# PIC32CX2051MTSH128S1 register map
Vendor: Microchip Technology; Series: PIC32CXMTSH; File version: 0
CPU: CM4 r0p1, selectable endian, MPU, FPU, 4 interrupt priority bits
Registers are 32-bit, read-write, reset 0x0 unless marked. A register's access mark holds for its fields unless they carry their own. Offsets are from the block's base; [hi:lo] are bit positions; {n}, {i} and the like mark numbered series; 'fields as' and 'values as' point back to an identical list.

## SUPC — Supply Controller
Base 0x400531D0; register names take the prefix SUPC_
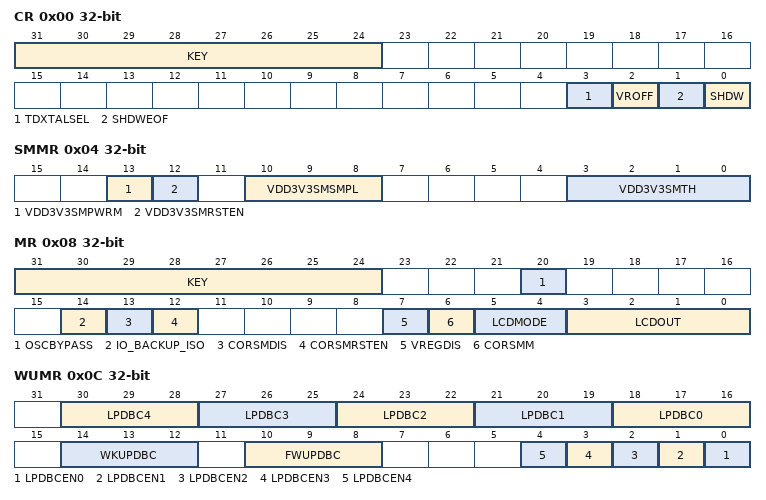
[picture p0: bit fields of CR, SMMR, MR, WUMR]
0x00 CR wo — Control Register
  [31:24] KEY — Password
    165=PASSWD (Writing any other value in this field aborts the write operation.)
  [3] TDXTALSEL — Timing Domain Slow Clock Selector
    0=RC (Slow clock of the timing domain is driven by the embedded 32 kHz (typical) RC oscillator.); 1=XTAL (Slow clock of the timing domain is driven by the 32.768 kHz crystal oscillator.)
  [2] VROFF — Voltage Regulator Off
    0=NO_EFFECT; 1=STOP_VREG (If KEY=0xA5, VROFF asserts the VDDCORE domain reset and stops the voltage regulator.)
  [1] SHDWEOF — Shutdown End Of Frame
  [0] SHDW — Shutdown
0x04 SMMR — Supply Monitor Mode Register
  [13] VDD3V3SMPWRM — VDD3V3 Supply Monitor Power Supply Mode
    0=MANUAL (The VDDBU power source selection is controlled by configuring the bit RSTC_MR.PWRSW.); 1=AUTO_VDD3V3SM (The VDDBU power source is VBAT when a VDD3V3 undervoltage is detected by the VDD3V3 supply monitor.)
  [12] VDD3V3SMRSTEN — VDD3V3 Supply Monitor Reset Enable
  [10:8] VDD3V3SMSMPL — VDD3V3 Supply Monitor Sampling Period
    0=DISABLED (VDD3V3 supply monitor is disabled); 1=ALWAYS_ON (Continuous VDD3V3 supply monitoring); 2=_32SLCK (VDD3V3 supply monitor is enabled for 1 period every 32 MD_SLCK periods Energy optimization in Backup mode with VDD3V3 supplied.); 3=_256SLCK (VDD3V3 supply monitor is enabled for 1 period every 256 MD_SLCK periods Energy optimization in Backup mode with VDD3V3 supplied.); 4=_2048SLCK (VDD3V3 supply monitor is enabled for 1 period every 2048 MD_SLCK periods Energy optimization in Backup mode with VDD3V3 supplied.)
  [3:0] VDD3V3SMTH — VDD3V3 Supply Monitor Threshold
0x08 MR — Mode Register
  [31:24] KEY — Password Key
    89=PASSWD1 (Modifies the VREGDIS bit. Other bits are not affected.); 165=PASSWD (Writing any other value in this field aborts the write operation.)
  [20] OSCBYPASS — Slow Crystal Oscillator Bypass
    0=NO_EFFECT (No effect. Clock selection depends on the value of the bit SUPC_CR.TDXTALSEL.); 1=BYPASS (The slow crystal oscillator is bypassed if SUPC_CR.TDXTALSEL=1. The bit OSCBYPASS must be set prior to setting the bit TDXTALSEL.)
  [14] IO_BACKUP_ISO — Backup Domain IO Isolation Control
  [13] CORSMDIS — VDDCORE Supply Monitor Disable
  [12] CORSMRSTEN — VDDCORE Supply Monitor Reset Enable
  [7] VREGDIS — Internal VDDCORE Voltage Regulator Disable
    0=INT_VREG (Internal VDDCORE voltage regulator is enabled.); 1=EXT_VREG (Internal VDDCORE voltage regulator is disabled (external power supply is used).)
  [6] CORSMM — VDDCORE Supply Monitor Output Mode
    0=NO_EFFECT (VDDCORE supply monitor output value has no effect. Power-on is performed whatever the value of the supply monitor output.); 1=VALID_VDD (VDDCORE supply monitor output value is checked to validate the VDDCORE domain power-on.)
  [5:4] LCDMODE — LCD Controller Mode of Operation
    0=LCDOFF (The internal supply source and the external supply source are both deselected (OFF Mode).); 2=LCDON_EXTVR (The external supply source for LCD (VDDLCD) is selected (the embedded LCD voltage regulator is in High-impedance mode).); 3=LCDON_INVR (The internal voltage regulator for VDDLCD is selected (Active mode).)
  [3:0] LCDOUT — LCD Voltage Regulator Output
0x0C WUMR — Wakeup Mode Register
  [3n+18:3n+16] LPDBC{n} (n=0..4) — Low-power Debouncer Period of WKUPx
    0=DISABLE (Disables the low-power debouncers.); {v}=_{v+1}_RTCOUT (WKUPx in active state for at least {v+1} RTCOUTx clock periods) (v=1..7)
  [14:12] WKUPDBC — Wake-up Inputs Debouncer Period
    0=IMMEDIATE (Immediate, no debouncing, detected active at least on one Slow Clock edge.); 1=_3_SK (WKUPx shall be in its active state for at least 3 MD_SLCK periods); 2=_32_SK (WKUPx shall be in its active state for at least 32 MD_SLCK periods); 3=_512_SK (WKUPx shall be in its active state for at least 512 MD_SLCK periods); 4=_4096_SK (WKUPx shall be in its active state for at least 4,096 MD_SLCK periods); 5=_32768_SK (WKUPx shall be in its active state for at least 32,768 MD_SLCK periods)
  [10:8] FWUPDBC — Force Wake-up Inputs Debouncer Period
    values as WKUPDBC
  [n] LPDBCEN{n} (n=0..4) — Tamper Enable for WKUPx Pin
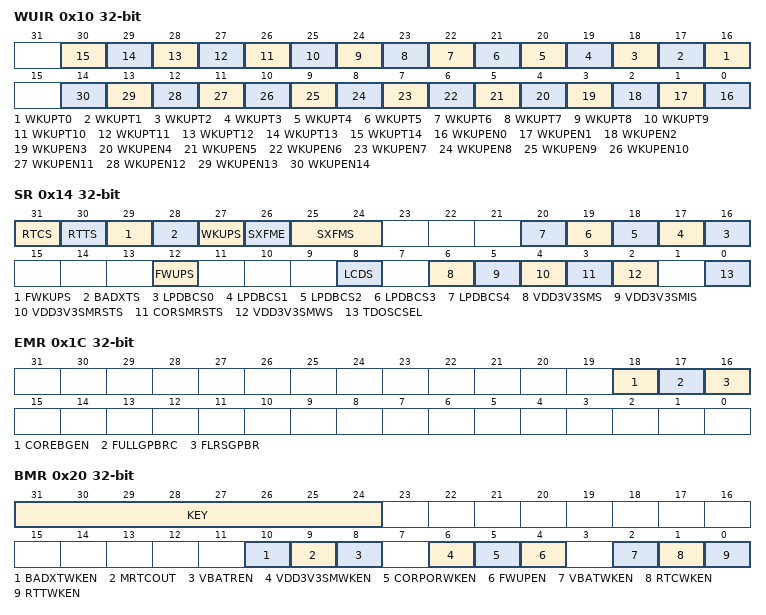
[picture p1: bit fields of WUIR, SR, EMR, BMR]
0x10 WUIR — Wakeup Inputs Register
  [n+16] WKUPT{n} (n=0..14) — Wake-up Input Type {n}
    0=LOW (A falling edge followed by a low level for a period defined by WKUPDBC on the corresponding wake-up input forces the wake-up of the core power supply.); 1=HIGH (A rising edge followed by a high level for a period defined by WKUPDBC on the corresponding wake-up input forces the wake-up of the core power supply.)
  [n] WKUPEN{n} (n=0..14) — Wake-up Input Enable {n}
0x14 SR ro — Status Register
  [31] RTCS — RTC Wake-up Status (cleared by reading SUPC_WUSR)
  [30] RTTS — RTT Wake-up Status (cleared by reading SUPC_WUSR)
  [29] FWKUPS — FWUP Wake-up Status (cleared by reading SUPC_WUSR)
  [28] BADXTS — Slow Crystal Oscillator Wake-up Status (cleared by reading SUPC_WUSR)
  [27] WKUPS — WKUP Wake-up Status (cleared by reading SUPC_WUSR)
  [26] SXFME — Slow Crystal Oscillator Frequency Monitor Error (cleared on read)
  [25:24] SXFMS — Slow Crystal Oscillator Frequency Monitor Status (cleared on read)
    0=GOOD (No frequency error detected.); 1=FREQ_ERROR (The frequency has not been correct over 4 consecutive monitoring periods but there are still edges detected on the slow crystal oscillator output.); 2=FAIL (No edge detected in the slow crystal oscillator output for at least 2 consecutive monitoring periods.)
  [n+16] LPDBCS{n} (n=0..4) — Tamper Detection Wake-up Status (cleared by reading SUPC_ISR)
  [12] FWUPS — Force Wake-up Pin Status
  [8] LCDS — LCD Power Domain Status
  [6] VDD3V3SMS — VDD3V3 Supply Monitor Output Status
  [5] VDD3V3SMIS — VDD3V3 Supply Monitor Interrupt Status (cleared by reading SUPC_ISR)
  [4] VDD3V3SMRSTS — VDD3V3 Supply Monitor Reset Status (cleared by reading SUPC_WUSR)
  [3] CORSMRSTS — VDDCORE Supply Monitor Reset Status (cleared by reading SUPC_WUSR)
  [2] VDD3V3SMWS — VDD3V3 Supply Monitor Wake-up Status (cleared by reading SUPC_WUSR)
  [0] TDOSCSEL — Timing Domain 32 kHz Oscillator Selection Status
    0=RC (The timing domain slow clock (TD_SLCK) source is the slow RC oscillator output.); 1=XTAL (The timing domain slow clock source is the 32.768 kHz crystal oscillator output.)
0x1C EMR — Extended Mode Register
  [18] COREBGEN — VDDCORE Voltage Regulator Bandgap Enable
  [17] FULLGPBRC — Full GPBR Clean
  [16] FLRSGPBR — Flash Erase GPBR
0x20 BMR — Backup Mode Register
  [31:24] KEY — Password Key
    values as CR.KEY
  [10] BADXTWKEN — Slow Crystal Oscillator Frequency Error Wake-up Enable
  [9] MRTCOUT — RTCOUT0 Outputs Drive Mode
    0=USERDEF (RTCOUT0 output is driven according to the configuration of the field RTC_MR.OUT0.)
  [8] VBATREN — Battery Voltage Event Report Enable
    0=DISABLE (Disables the report of event on VBAT voltage.); 1=ENABLE (Enables the report of event on VBAT voltage.)
  [6] VDD3V3SMWKEN — VDD3V3 Supply Monitor Wake-up Enable
    0=DISABLE (Wake-up on VDD3V3 supply monitor under voltage detection is disabled.); 1=ENABLE (Wake-up on VDD3V3 supply monitor under voltage detection is enabled.)
  [5] CORPORWKEN — VDDCORE POR Wake-up Enable
    0=DISABLE (Wake-up on VDDCORE Power-On Reset Event is disabled.); 1=ENABLE (Wake-up on VDDCORE Power-On Reset Event is enabled.)
  [4] FWUPEN — Force Wake-up Pin Wake-up Enable
    0=DISABLE (The fwup signal has no wake-up effect.); 1=ENABLE (The fwup signal forces the wake-up of the core power supply.)
  [2] VBATWKEN — VBAT Supply Monitor Wake-up Enable
    0=DISABLE (Wake-up on VBAT supply monitor under voltage detection is disabled.); 1=ENABLE (Wake-up on VBAT supply monitor under voltage detection is enabled.)
  [1] RTCWKEN — Real-time Clock Wake-up Enable
    0=DISABLE (The RTC alarm signal has no wake-up effect.); 1=ENABLE (The RTC alarm signal forces the wake-up of the core power supply.)
  [0] RTTWKEN — Real-time Timer Wake-up Enable
    0=DISABLE (The RTT alarm signal has no wake-up effect.); 1=ENABLE (The RTT alarm signal forces the wake-up of the core power supply.)
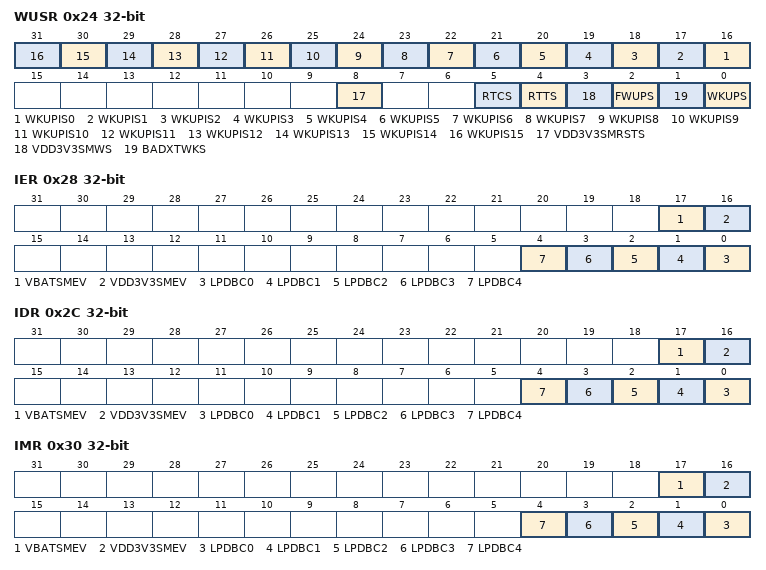
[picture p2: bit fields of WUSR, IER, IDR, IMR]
0x24 WUSR ro — Wakeup Status Register
  [n+16] WKUPIS{n} (n=0..15) — WKUPx Input Wake-up Status (cleared on read)
  [8] VDD3V3SMRSTS — VDD3V3 Supply Monitor Reset Status (cleared on read)
  [5] RTCS — RTC Wake-up Status (cleared on read)
  [4] RTTS — RTT Wake-up Status (cleared on read)
  [3] VDD3V3SMWS — VDD3V3 Supply Monitor Wake-up Status (cleared on read)
  [2] FWUPS — FWUP Wake-up Status (cleared on read)
  [1] BADXTWKS — Slow Crystal Oscillator Frequency Error Wake-up Status (cleared on read)
  [0] WKUPS — WKUP Wake-up Status (cleared on read)
0x28 IER wo — Enable Interrupt Register
  [17] VBATSMEV — VBAT Supply Monitor Event Interrupt Enable
  [16] VDD3V3SMEV — VDD3V3 Supply Monitor Event Interrupt Enable
  [n] LPDBC{n} (n=0..4) — WKUPx Pin Tamper Detection Interrupt Enable
0x2C IDR wo — Disable Interrupt Register
  [17] VBATSMEV — VBAT Supply Monitor Event Interrupt Disable
  [16] VDD3V3SMEV — VDD3V3 Supply Monitor Event Interrupt Disable
  [n] LPDBC{n} (n=0..4) — WKUPx Pin Tamper Detection Interrupt Disable
0x30 IMR ro — Mask Interrupt Register
  [17] VBATSMEV — VBAT Supply Monitor Event Interrupt Mask
  [16] VDD3V3SMEV — VDD3V3 Supply Monitor Event Interrupt Mask
  [n] LPDBC{n} (n=0..4) — WKUPx Pin Tamper Detection Interrupt Mask
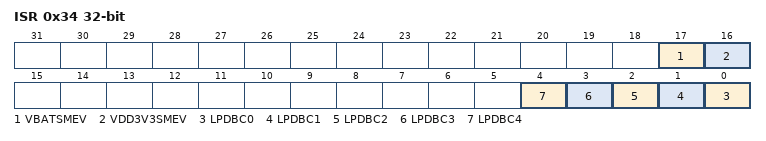
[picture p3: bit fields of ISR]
0x34 ISR ro — Status Interrupt Register
  [17] VBATSMEV — VBAT Supply Monitor Event Interrupt Status (cleared on read)
  [16] VDD3V3SMEV — VDD3V3 Supply Monitor Event Interrupt Status (cleared on read)
  [n] LPDBC{n} (n=0..4) — WKUPx Pin Tamper Detection Interrupt Status (cleared on read)
